# ADC register map
Vendor: Texas Instruments
Peripheral module from a debugger description file (folder DM50x).
Registers are 32-bit, read-write, reset values left out (the file's numbers can be read two ways) unless marked. A register's access mark holds for its fields unless they carry their own. Offsets are as the file gives them; lines under a group give offsets from that group; [hi:lo] are bit positions; {n}, {i} and the like mark numbered series; 'fields as' and 'values as' point back to an identical list; <NAME> marks a mode.

## ADC
0x00 ADC_REVISION ro — Revision identifier
  [31:0] REVISION — IP revision
0x10 ADC_SYSCONFIG access per field — System configuration register
  [3:2] IDLEMODE rw — 0x0: Force-idle: An IDLE request is acknowledged unconditionally.
    1=No-idle: An IDLE request is never acknowledged; 2=Smart-idle: The acknowledgment to an IDLE request is given based on the internal activity; 3=SmartIdleWakeup (Reserved)
0x20 ADC_IRQ_EOI access per field — Software end of interrupt.
  [0] LINE_NUMBER wo — Software End Of Interrupt (EOI) control.
    0=EOI_1 (EOI for interrupt line number 0. Read returns 0.)
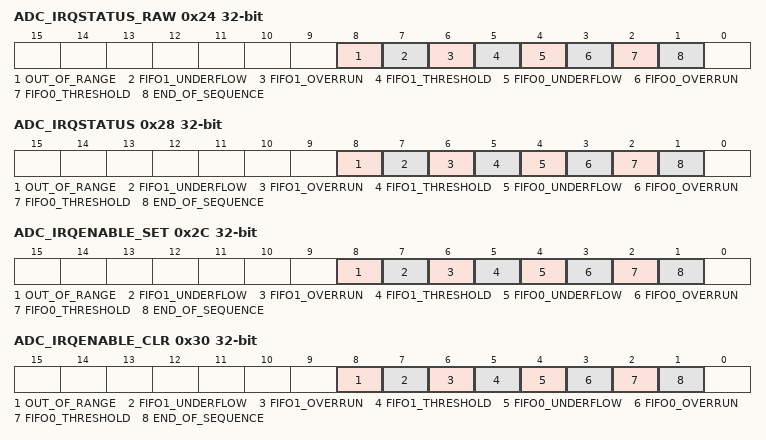
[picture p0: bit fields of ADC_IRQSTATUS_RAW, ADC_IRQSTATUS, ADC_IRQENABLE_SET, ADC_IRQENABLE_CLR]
0x24 ADC_IRQSTATUS_RAW — Per-event raw interrupt status vector, showing all active events (enabled and not enabled)
  [8] OUT_OF_RANGE — Status raw for interrupt. Write 0: No action Write 1: Set event (debug) Read 0: No event pending Read 1: Event pending
  [7] FIFO1_UNDERFLOW — Status raw for interrupt. Write 0: No action Write 1: Set event (debug) Read 0: No event pending Read 1: Event pending
  [6] FIFO1_OVERRUN — Status raw for interrupt. Write 0: No action Write 1: Set event (debug) Read 0: No event pending Read 1: Event pending
  [5] FIFO1_THRESHOLD — Status raw for interrupt. Write 0: No action Write 1: Set event (debug) Read 0: No event pending Read 1: Event pending
  [4] FIFO0_UNDERFLOW — Status raw for interrupt. Write 0: No action Write 1: Set event (debug) Read 0: No event pending Read 1: Event pending
  [3] FIFO0_OVERRUN — Status raw for interrupt. Write 0: No action Write 1: Set event (debug) Read 0: No event pending Read 1: Event pending
  [2] FIFO0_THRESHOLD — Status raw for interrupt. Write 0: No action Write 1: Set event (debug) Read 0: No event pending Read 1: Event pending
  [1] END_OF_SEQUENCE — Status raw for interrupt. Write 0: No action Write 1: Set event (debug) Read 0: No event pending Read 1: Event pending
0x28 ADC_IRQSTATUS — Per-event “enabled” status register vector. The enabled status isn’t set unless the event is enabled.
  [8] OUT_OF_RANGE — Enabled status for interrupt. Write 0: No action Write 1: Clear (raw) event Read 0: No (enabled) event pending Read 1: Event pending
  [7] FIFO1_UNDERFLOW — Enabled status for interrupt. Write 0: No action Write 1: Clear (raw) event Read 0: No (enabled) event pending Read 1: Event pending
  [6] FIFO1_OVERRUN — Enabled status for interrupt. Write 0: No action Write 1: Clear (raw) event Read 0: No (enabled) event pending Read 1: Event pending
  [5] FIFO1_THRESHOLD — Enabled status for interrupt. Write 0: No action Write 1: Clear (raw) event Read 0: No (enabled) event pending Read 1: Event pending
  [4] FIFO0_UNDERFLOW — Enabled status for interrupt. Write 0: No action Write 1: Clear (raw) event Read 0: No (enabled) event pending Read 1: Event pending
  [3] FIFO0_OVERRUN — Enabled status for interrupt. Write 0: No action Write 1: Clear (raw) event Read 0: No (enabled) event pending Read 1: Event pending
  [2] FIFO0_THRESHOLD — Enabled status for interrupt. Write 0: No action Write 1: Clear (raw) event Read 0: No (enabled) event pending Read 1: Event pending
  [1] END_OF_SEQUENCE — Enabled status for interrupt. Write 0: No action Write 1: Clear (raw) event Read 0: No (enabled) event pending Read 1: Event pending
0x2C ADC_IRQENABLE_SET — Per-event interrupt enable bit vector
  [8] OUT_OF_RANGE — Interrupt enable. Write 0: No action Write 1: Enable interrupt Read 0: Interrupt disabled (masked) Read 1: Interrupt enabled
  [7] FIFO1_UNDERFLOW — Interrupt enable. Write 0: No action Write 1: Enable interrupt Read 0: Interrupt disabled (masked) Read 1: Interrupt enabled
  [6] FIFO1_OVERRUN — Interrupt enable. Write 0: No action Write 1: Enable interrupt Read 0: Interrupt disabled (masked) Read 1: Interrupt enabled
  [5] FIFO1_THRESHOLD — Interrupt enable. Write 0: No action Write 1: Enable interrupt Read 0: Interrupt disabled (masked) Read 1: Interrupt enabled
  [4] FIFO0_UNDERFLOW — Interrupt enable. Write 0: No action Write 1: Enable interrupt Read 0: Interrupt disabled (masked) Read 1: Interrupt enabled
  [3] FIFO0_OVERRUN — Interrupt enable. Write 0: No action Write 1: Enable interrupt Read 0: Interrupt disabled (masked) Read 1: Interrupt enabled
  [2] FIFO0_THRESHOLD — Interrupt enable. Write 0: No action Write 1: Enable interrupt Read 0: Interrupt disabled (masked) Read 1: Interrupt enabled
  [1] END_OF_SEQUENCE — Interrupt enable. Write 0: No action Write 1: Enable interrupt Read 0: Interrupt disabled (masked) Read 1: Interrupt enabled
0x30 ADC_IRQENABLE_CLR — Per-event interrupt disable bit vector
  [8] OUT_OF_RANGE — Interrupt disable. Write 0: No action Write 1: Disable interrupt Read 0: Interrupt disabled (masked) Read 1: Interrupt enabled
  [7] FIFO1_UNDERFLOW — Interrupt disable. Write 0: No action Write 1: Disable interrupt Read 0: Interrupt disabled (masked) Read 1: Interrupt enabled
  [6] FIFO1_OVERRUN — Interrupt disable. Write 0: No action Write 1: Disable interrupt Read 0: Interrupt disabled (masked) Read 1: Interrupt enabled
  [5] FIFO1_THRESHOLD — Interrupt disable. Write 0: No action Write 1: Disable interrupt Read 0: Interrupt disabled (masked) Read 1: Interrupt enabled
  [4] FIFO0_UNDERFLOW — Interrupt disable. Write 0: No action Write 1: Disable interrupt Read 0: Interrupt disabled (masked) Read 1: Interrupt enabled
  [3] FIFO0_OVERRUN — Interrupt disable. Write 0: No action Write 1: Disable interrupt Read 0: Interrupt disabled (masked) Read 1: Interrupt enabled
  [2] FIFO0_THRESHOLD — Interrupt disable. Write 0: No action Write 1: Disable interrupt Read 0: Interrupt disabled (masked) Read 1: Interrupt enabled
  [1] END_OF_SEQUENCE — Interrupt disable. Write 0: No action Write 1: Disable interrupt Read 0: Interrupt disabled (masked) Read 1: Interrupt enabled
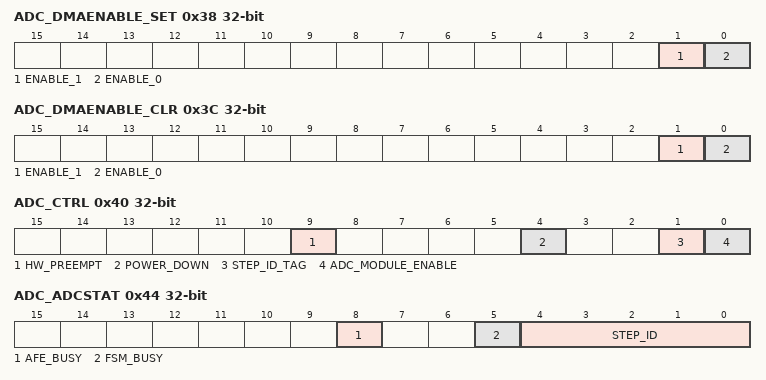
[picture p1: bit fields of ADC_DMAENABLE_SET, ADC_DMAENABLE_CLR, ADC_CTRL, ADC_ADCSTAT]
0x38 ADC_DMAENABLE_SET — Per-line DMA enable bit vector.
  [1] ENABLE_1 — Enable DMA request FIFO 1 Write 0: No action Write 1: Enable DMA line Read 0: DMA line disabled Read 1: DMA line enabled
  [0] ENABLE_0 — Enable DMA request FIFO 0 Write 0: No action Write 1: Enable DMA line Read 0: DMA line disabled Read 1: DMA line enabled
0x3C ADC_DMAENABLE_CLR — Per-line DMA disable bit vector.
  [1] ENABLE_1 — Disable DMA request FIFO 1 Write 0: No action Write 1: Disable DMA line Read 0: DMA line disabled Read 1: DMA line enabled
  [0] ENABLE_0 — Disable DMA request FIFO 0 Write 0: No action Write 1: Disable DMA line Read 0: DMA line disabled Read 1: DMA line enabled
0x40 ADC_CTRL access per field — ADC control register
  [9] HW_PREEMPT rw — 0: SW steps are not preempted by HW events 1: SW steps are preempted by HW events HW EVENTS ARE NOT SUPPORTED IN THIS DEVICE
  [4] POWER_DOWN rw — ADC Power Down control 0: AFE is powered up 1 : AFE is powered down (default) At default, AFE is powered down; Software must write 0 to turn on the power and wait 4 us before starting a conversion
  [1] STEP_ID_TAG rw — Writing 1 to this bit will store the Step ID number with the captured ADC data in the FIFO. 0: write zeros 1: store the channel id tag
  [0] ADC_MODULE_ENABLE rw — ADC module enable bit. After programming all the steps and configuration registers, write a 1 to this bit to start conversion. Writing a 0 will disable the module (after the current conversion completes)
0x44 ADC_ADCSTAT ro — ADC sequencer status. Software can read this register to find out the currently scheduled step id being converted on the ADC port. If desired to turn the controller off and then back on, then the STEP_ID bit should be checked and compared to IDLE state before enabling the ADC module again. Also, before enabling the ADC, the user should wait for the FSM_BUSY bit to read idle.
  [8] AFE_BUSY — Monitor the AFE internal calibration (busy bit)
  [5] FSM_BUSY — Status of OCP FSM and ADC FSM 0: idle 1: busy (conversion in progress)
  [4:0] STEP_ID — 0x10: Idle 0x11 – 0x1F: Reserved 0x0 – 0xF: Step 1 – Step 16
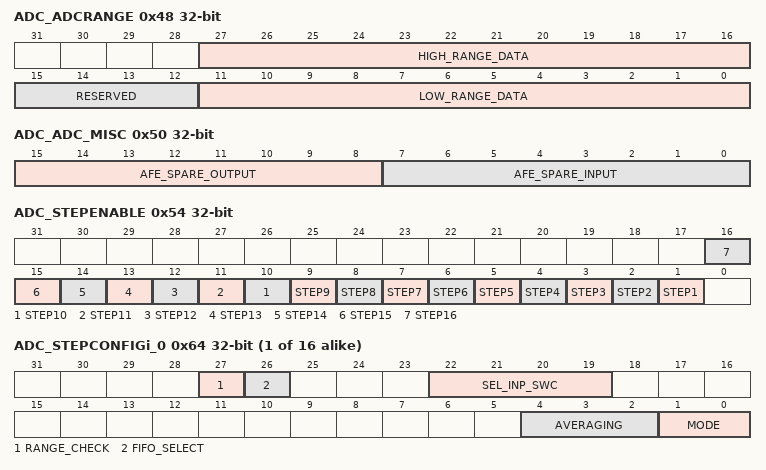
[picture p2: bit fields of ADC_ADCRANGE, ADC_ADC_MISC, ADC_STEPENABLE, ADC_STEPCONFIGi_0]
0x48 ADC_ADCRANGE access per field — ADC range check register. This feature requires the range check interrupt bit to be enabled first. Also, the user can decide which channel input is compared by programming the RANGE_CHECK bit of the registers. It is up to software to sort through FIFO data to determine which channel data was out of range.
  [27:16] HIGH_RANGE_DATA rw — Sampled ADC data is compared to this value. If the sampled data is &gt; HIGH_RANGE_DATA, then interrupt is generated.
  [15:12] RESERVED ro — Reseved
  [11:0] LOW_RANGE_DATA rw — Sampled ADC data is compared to this value. If the sampled data is &lt; LOW_RANGE_DATA, then interrupt is generated.
0x4C ADC_ADC_CLKDIV access per field — The ADC_CLK input will go through this clock divider first before being sent to the AFE clock input . The ADC clock should be 6× slower than OCP clock.
  [11:0] ADC_CLKDIV rw — The input ADC clock will be divided by this value and sent to the AFE. Program to the value minus 1
0x50 ADC_ADC_MISC access per field — Zero Offset Correction Using Efuse: Pro: – Covers the ground bounce due to package routing. Con: – one- time calibration; doesn’t take into account the Si degradation over time – T-V variation not accounted Zero Offset Correction using Internal Calibration: Pro: – Dynamic Calibration – Accounts for device ageing, temperature and Voltage variation Con: – 320 clk cycles after every Power up un-usable for actual data conversion
  [15:8] AFE_SPARE_OUTPUT ro — Connected to AFE Spare Output pins.
  [7:0] AFE_SPARE_INPUT rw — Connected to AFE Spare Input pins. bit 0: Error correction 0: disable 1: enable bit 1: Calibration 0: Use internal calibration 1: Use eFuse for offset bit 2: Internal calibration start (then monitor ADC_ADCSTAT[8] AFE_BUSY to see when AFE is finished with calibration. This is a one time event after power up) 0: No action 1: Start internal calibration
0x54 ADC_STEPENABLE access per field — This register contains the enable bit for each step in the sequencer. When all steps are disabled, the FSM will stay in IDLE state. These bits can be enabled or disabled dynamically during operation. When a write to this register occurs during operational mode, the HW will make sure the new settings are updated after the END_OF_SEQUENCE event (registers are shadowed and updated at that time). If a step is configured in one-shot mode, the HW will automatically reset the STEPi bit after it is scheduled.
  [n] STEP{n} rw (n=1..16) — Enable step {n}
{0x64+8i} ADC_STEPCONFIGi_{i} (i=0..15) — Values sent to the AFE during step i.
  [27] RANGE_CHECK — 0: Disable out-of-range check 1: Compare ADC data with ADC_ADCRANGE register
  [26] FIFO_SELECT — Sampled data will be stored in FIFO. 0: FIFO 0 1: FIFO 1
  [22:19] SEL_INP_SWC — SEL_INP pins SW configuration. 0x0 = Channel 1 0x1 = Channel 2 0x2 = Channel 3 0x3 = Channel 4 0x4 = Channel 5 0x5 = Channel 6 0x6 = Channel 7 0x7 = Channel 8 0x8 = VREFN all other values = VREFN.
  [4:2] AVERAGING — Number of samplings to average: 0x0: no average 0x1: 2 samples average 0x2: 4 samples average 0x3: 8 samples average 0x4: 16 samples average
  [1:0] MODE — 0x0: SW enabled, one-shot 0x1: SW enabled, continuous 0x2: HW synchronized, one-shot (NOT SUPPORTED IN THIS DEVICE) 0x3: HW synchronized, continuous (NOT SUPPORTED IN THIS DEVICE)
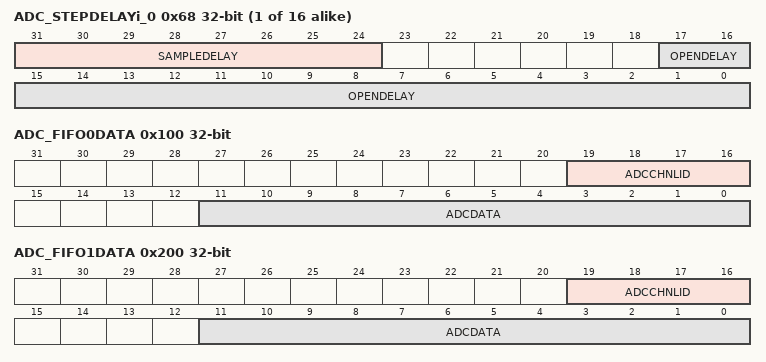
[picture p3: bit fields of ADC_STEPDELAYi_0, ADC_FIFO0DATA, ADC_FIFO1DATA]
{0x68+8i} ADC_STEPDELAYi_{i} (i=0..15) — Step i delay register
  [31:24] SAMPLEDELAY — This register will control the number of ADC clock cycles to hold SOC high. Any value programmed here will be added to the minimum requirement of 1 clock cycle.
  [17:0] OPENDELAY — Program the number of ADC clock cycles to wait after applying the step configuration registers and before sending the start of ADC conversion (SOC)
0xE4 ADC_FIFO0COUNT ro — FIFO0 word count register
  [6:0] WORDS_IN_FIFO — Number of words currently in the FIFO0
0xE8 ADC_FIFO0THRESHOLD — FIFO0 threshold level register
  [5:0] FIFO_THRESHOLD_LEVEL — Program the desired FIFO0 data sample level to reach before generating interrupt to CPU (program to value minus 1)
0xEC ADC_DMA0REQ — FIFO0 DMA request level register
  [5:0] DMA_REQUEST_LEVEL — Number of words in FIFO0 before generating a DMA request (program to value minus 1)
0xF0 ADC_FIFO1COUNT ro — FIFO1 word count register
  [6:0] WORDS_IN_FIFO — Number of words currently in the FIFO1
0xF4 ADC_FIFO1THRESHOLD — FIFO1 threshold level register
  [5:0] FIFO_THRESHOLD_LEVEL — Program the desired FIFO1 data sample level to reach before generating interrupt to CPU (program to value minus 1)
0xF8 ADC_DMA1REQ — FIFO1 DMA request level register
  [5:0] DMA_REQUEST_LEVEL — Number of words in FIFO1 before generating a DMA request (program to value minus 1)
0x100 ADC_FIFO0DATA ro — The CPU can read from this register to read data in FIFO 0. A read from this register will auto increment the FIFO read pointer. If software reads when FIFO is empty, an underflow interrupt will be triggered. All of the ADC conversions will be output as positive binary values.
  [19:16] ADCCHNLID — Optional ID tag of channel that captured the data. If tag option is disabled, these bits will be 0. 0x0: Step 1; 0x1: Step2;...; 0xF: Step 16.
  [11:0] ADCDATA — 12 bit sampled ADC converted data value stored in FIFO 0
0x200 ADC_FIFO1DATA ro — The CPU can read from this register to read data in FIFO 1. A read from this register will auto increment the FIFO read pointer. If software reads when FIFO is empty, an underflow interrupt will be triggered. All of the ADC conversions will be output as positive binary values.
  [19:16] ADCCHNLID — Optional ID tag of channel that captured the data. If tag option is disabled, these bits will be 0. 0x0: Step 1; 0x1: Step2;...; 0xF: Step 16.
  [11:0] ADCDATA — 12 bit sampled ADC converted data value stored in FIFO 1
